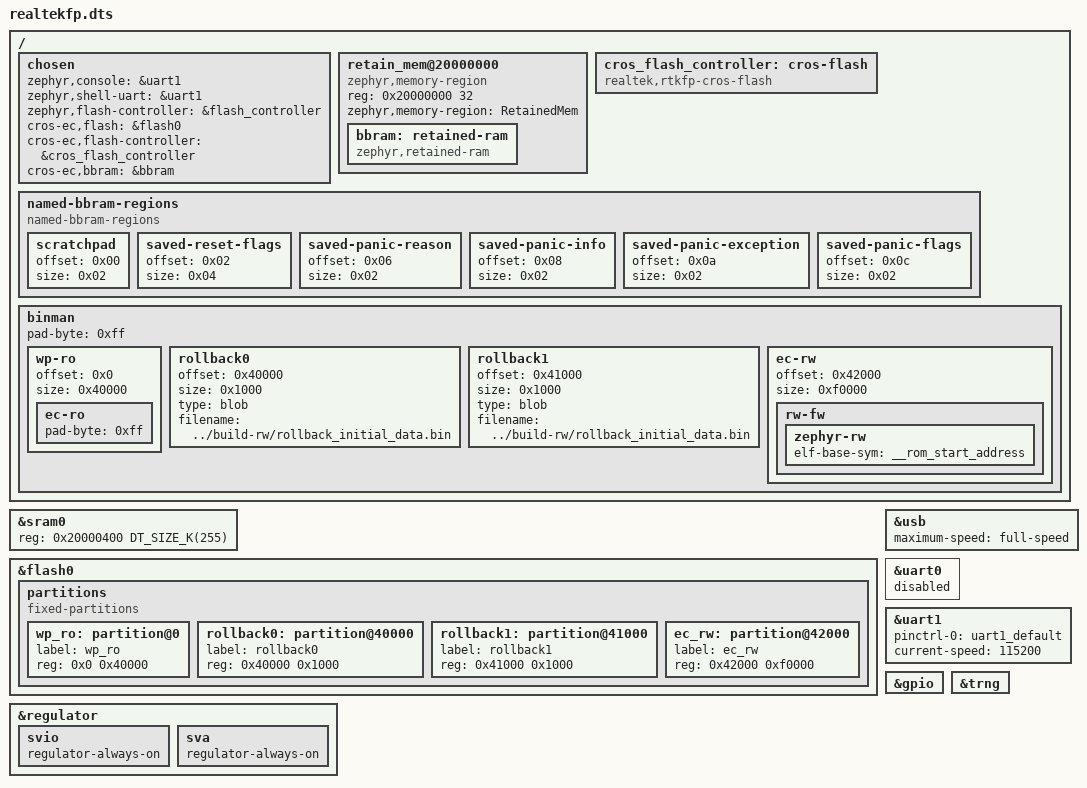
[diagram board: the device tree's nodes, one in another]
/* Copyright 2026 The ChromiumOS Authors.
 * Use of this source code is governed by a BSD-style license that can be
 * found in the LICENSE file.
 */

#include <cros/binman.dtsi>

#include "gpio.dtsi"
#include "rwsig.dtsi"

#include <cros/integrated_fwid.dtsi>

/ {
	chosen {
		zephyr,console = &uart1;
		zephyr,shell-uart = &uart1;
		zephyr,flash-controller = &flash_controller;
		cros-ec,flash = &flash0;
		cros-ec,flash-controller = &cros_flash_controller;
		cros-ec,bbram = &bbram;
	};

	retain_mem@20000000 {
		compatible = "zephyr,memory-region", "mmio-sram";
		reg = <0x20000000 32>;
		zephyr,memory-region = "RetainedMem";
		status = "okay";

		bbram: retained-ram {
			compatible = "zephyr,retained-ram";
			status = "okay";
			#address-cells = <1>;
			#size-cells = <1>;
		};
	};

	cros_flash_controller: cros-flash {
		compatible = "realtek,rtkfp-cros-flash";
	};

	named-bbram-regions {
		compatible = "named-bbram-regions";

		scratchpad {
			offset = <0x00>;
			size = <0x02>;
		};
		saved-reset-flags {
			offset = <0x02>;
			size = <0x04>;
		};
		saved-panic-reason {
			offset = <0x06>;
			size = <0x02>;
		};
		saved-panic-info {
			offset = <0x08>;
			size = <0x02>;
		};
		saved-panic-exception {
			offset = <0x0a>;
			size = <0x02>;
		};
		saved-panic-flags {
			offset = <0x0c>;
			size = <0x02>;
		};
	};

	binman {
		pad-byte = <0xff>;

		/* First 64 sectors (64 x 4KB, 256KB) used for RO */
		wp-ro {
			offset = <0x0>;
			size = <0x40000>;
			ec-ro {
				pad-byte = <0xff>;
			};
		};

		/* Two sectors used for rollback (4KB each) */
		rollback0 {
			offset = <0x40000>;
			size = <0x1000>;
			type = "blob";
			filename = "../build-rw/rollback_initial_data.bin";
		};

		rollback1 {
			offset = <0x41000>;
			size = <0x1000>;
			type = "blob";
			filename = "../build-rw/rollback_initial_data.bin";
		};

		/* 240 sectors (240 * 4KB, 960KB) used for RW */
		ec-rw {
			offset = <0x42000>;
			size = <0xf0000>;
			rw-fw {
				/*
				 * Clang doesn't emit STT_SECTION symbols (also
				 * called 'section symbols'), so 'rom_start'
				 * symbol is not available. Fortunately, Zephyr
				 * linker scripts provide '__rom_start_address'
				 * symbol which points to the beginning of
				 * 'rom_start' section.
				 */
				zephyr-rw {
					elf-base-sym = "__rom_start_address";
				};
			};
		};
	};
};

&sram0 {
	reg = <0x20000400 DT_SIZE_K(255)>;
};

&flash0 {
	partitions {
		compatible = "fixed-partitions";
		#address-cells = <1>;
		#size-cells = <1>;

		wp_ro: partition@0 {
			label = "wp_ro";
			reg = <0x0 0x40000>;
		};

		rollback0: partition@40000 {
			label = "rollback0";
			reg = <0x40000 0x1000>;
		};

		rollback1: partition@41000 {
			label = "rollback1";
			reg = <0x41000 0x1000>;
		};

		ec_rw: partition@42000 {
			label = "ec_rw";
			reg = <0x42000 0xf0000>;
		};

	};
};

&usb {
	maximum-speed = "full-speed";
};

&uart0 {
	status = "disabled";
};

&uart1 {
	pinctrl-names = "default";
	pinctrl-0 = <&uart1_default>;
	current-speed = <115200>;
	status = "okay";
};

&regulator {
	status = "okay";
	svio {
		regulator-always-on;
	};

	sva {
		regulator-always-on;
	};

};

zephyr_udc0: &usb {
	status = "okay";
};

&gpio {
	status = "okay";
};

&trng {
	status = "okay";
};
